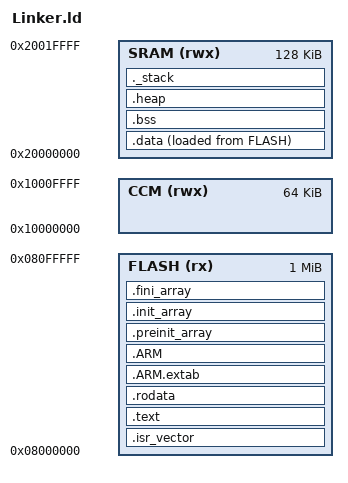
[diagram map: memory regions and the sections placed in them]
/*
 * Linker script for STM32F407VGT6
 *
 * Memory map:
 *   FLASH  - 1024K at 0x08000000  (main program storage)
 *   SRAM   - 128K  at 0x20000000  (112K + 16K contiguous)
 *   CCM    - 64K   at 0x10000000  (core-coupled memory, no DMA access)
 */

ENTRY(Reset_Handler)

_stack_size = 4K;
_heap_size  = 16K;

MEMORY
{
    FLASH (rx)  : ORIGIN = 0x08000000, LENGTH = 1024K
    SRAM  (rwx) : ORIGIN = 0x20000000, LENGTH = 128K
    CCM   (rwx) : ORIGIN = 0x10000000, LENGTH = 64K
}

SECTIONS
{
    /* Vector table must be at the start of FLASH */
    .isr_vector :
    {
        . = ALIGN(4);
        KEEP(*(.isr_vector))
        . = ALIGN(4);
    } > FLASH

    /* Program code */
    .text :
    {
        . = ALIGN(4);
        *(.text)
        *(.text*)
        *(.glue_7)
        *(.glue_7t)

        KEEP(*(.init))
        KEEP(*(.fini))

        . = ALIGN(4);
        _etext = .;
    } > FLASH

    /* Read-only data */
    .rodata :
    {
        . = ALIGN(4);
        *(.rodata)
        *(.rodata*)
        . = ALIGN(4);
    } > FLASH

    /* ARM exception handling */
    .ARM.extab :
    {
        *(.ARM.extab* .gnu.linkonce.armextab.*)
    } > FLASH

    .ARM :
    {
        __exidx_start = .;
        *(.ARM.exidx*)
        __exidx_end = .;
    } > FLASH

    /* C++ constructors */
    .preinit_array :
    {
        PROVIDE_HIDDEN(__preinit_array_start = .);
        KEEP(*(.preinit_array*))
        PROVIDE_HIDDEN(__preinit_array_end = .);
    } > FLASH

    .init_array :
    {
        PROVIDE_HIDDEN(__init_array_start = .);
        KEEP(*(SORT(.init_array.*)))
        KEEP(*(.init_array*))
        PROVIDE_HIDDEN(__init_array_end = .);
    } > FLASH

    .fini_array :
    {
        PROVIDE_HIDDEN(__fini_array_start = .);
        KEEP(*(SORT(.fini_array.*)))
        KEEP(*(.fini_array*))
        PROVIDE_HIDDEN(__fini_array_end = .);
    } > FLASH

    /* Initialized data: LMA in FLASH, VMA in SRAM */
    _sidata = LOADADDR(.data);

    .data :
    {
        . = ALIGN(4);
        _sdata = .;
        *(.data)
        *(.data*)
        . = ALIGN(4);
        _edata = .;
    } > SRAM AT> FLASH

    /* Uninitialized data (zeroed at startup) */
    .bss :
    {
        . = ALIGN(4);
        _sbss = .;
        __bss_start__ = _sbss;
        *(.bss)
        *(.bss*)
        *(COMMON)
        . = ALIGN(4);
        _ebss = .;
        __bss_end__ = _ebss;
    } > SRAM

    /* Heap grows up from end of BSS */
    .heap :
    {
        . = ALIGN(8);
        _heap_start = .;
        . = . + _heap_size;
        . = ALIGN(8);
        _heap_end = .;
    } > SRAM

    /* Stack at top of SRAM, grows downward */
    ._stack :
    {
        . = ALIGN(8);
        . = . + _stack_size;
        . = ALIGN(8);
        _estack = .;
    } > SRAM

    /* Discard debug sections from vendor code */
    /DISCARD/ :
    {
        libc.a(*)
        libm.a(*)
        libgcc.a(*)
    }
}
